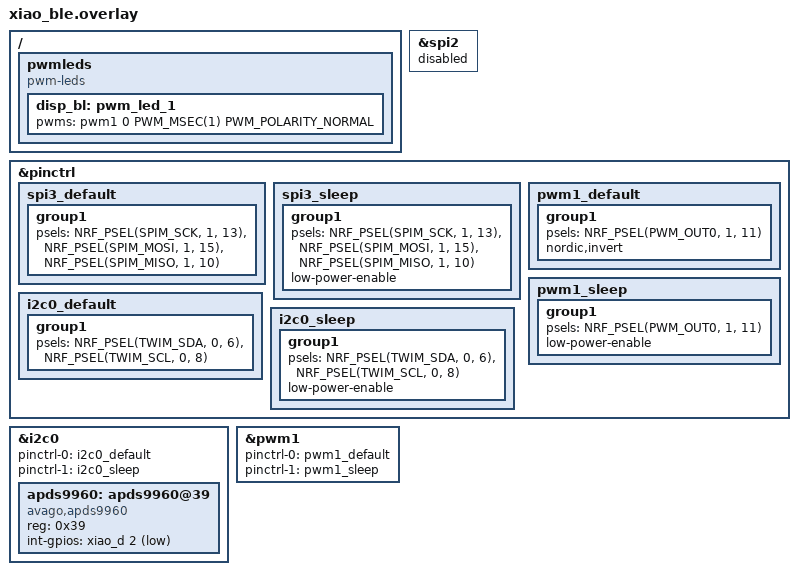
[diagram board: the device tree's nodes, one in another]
/ {
   pwmleds {
      compatible = "pwm-leds";
      disp_bl: pwm_led_1 {
          pwms = <&pwm1 0 PWM_MSEC(1) PWM_POLARITY_NORMAL>;
      };
  };
};

&spi2 {
   status = "disabled";
};

&pinctrl {
   spi3_default: spi3_default {
		group1 {
			psels = <NRF_PSEL(SPIM_SCK, 1, 13)>,
				<NRF_PSEL(SPIM_MOSI, 1, 15)>,
				<NRF_PSEL(SPIM_MISO, 1, 10)>;
		};
	};

	spi3_sleep: spi3_sleep {
		group1 {
			psels = <NRF_PSEL(SPIM_SCK, 1, 13)>,
				<NRF_PSEL(SPIM_MOSI, 1, 15)>,
				<NRF_PSEL(SPIM_MISO, 1, 10)>;
			low-power-enable;
		};
	};

   pwm1_default: pwm1_default {
      group1 {
         psels = <NRF_PSEL(PWM_OUT0, 1, 11)>;
         nordic,invert;
      };
   };

   pwm1_sleep: pwm1_sleep {
      group1 {
         psels = <NRF_PSEL(PWM_OUT0, 1, 11)>;
         low-power-enable;
      };
   };

   i2c0_default: i2c0_default {
      group1 {
         psels = <NRF_PSEL(TWIM_SDA, 0, 6)>,
                 <NRF_PSEL(TWIM_SCL, 0, 8)>;
      };
   };

   i2c0_sleep: i2c0_sleep {
      group1 {
         psels = <NRF_PSEL(TWIM_SDA, 0, 6)>,
                 <NRF_PSEL(TWIM_SCL, 0, 8)>;
         low-power-enable;
      };
   };
};

&i2c0 {
   status = "okay";
   pinctrl-0 = <&i2c0_default>;
   pinctrl-1 = <&i2c0_sleep>;
   pinctrl-names = "default", "sleep";

   apds9960: apds9960@39 {
       compatible = "avago,apds9960";
       status = "okay";
       reg = <0x39>;
       int-gpios = <&xiao_d 2 (GPIO_ACTIVE_LOW | GPIO_PULL_UP)>;
   };
};

&pwm1 {
  status = "okay";
  pinctrl-0 = <&pwm1_default>;
  pinctrl-1 = <&pwm1_sleep>;
  pinctrl-names = "default", "sleep";
};

